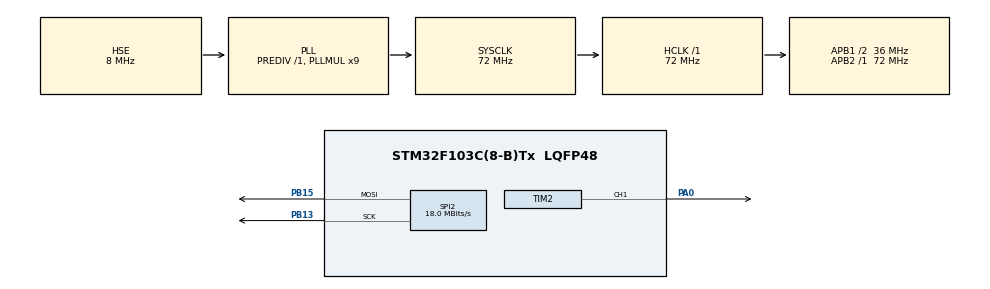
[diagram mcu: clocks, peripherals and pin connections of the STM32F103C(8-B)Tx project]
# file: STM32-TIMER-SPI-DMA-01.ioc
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Dma.Request0=SPI2_TX
Dma.SPI2_TX.0.Direction=DMA_MEMORY_TO_PERIPH
Dma.SPI2_TX.0.Instance=DMA1_Channel5
Dma.SPI2_TX.0.MemDataAlignment=DMA_MDATAALIGN_BYTE
Dma.SPI2_TX.0.MemInc=DMA_MINC_ENABLE
Dma.SPI2_TX.0.Mode=DMA_NORMAL
Dma.SPI2_TX.0.PeriphDataAlignment=DMA_PDATAALIGN_BYTE
Dma.SPI2_TX.0.PeriphInc=DMA_PINC_DISABLE
Dma.SPI2_TX.0.Priority=DMA_PRIORITY_LOW
Mcu.Family=STM32F1
Mcu.Name=STM32F103C(8-B)Tx
Mcu.Package=LQFP48
NVIC.DMA1_Channel5_IRQn=true\:0\:0\:false\:false\:true\:false\:true\:true
NVIC.PriorityGroup=NVIC_PRIORITYGROUP_4
NVIC.TIM2_IRQn=true\:0\:0\:false\:false\:true\:true\:true\:true
PA0-WKUP.Signal=S_TIM2_CH1_ETR
PA13.Mode=Serial_Wire
PA13.Signal=SYS_JTMS-SWDIO
PA14.Mode=Serial_Wire
PA14.Signal=SYS_JTCK-SWCLK
PB13.Mode=TX_Only_Simplex_Unidirect_Master
PB13.Signal=SPI2_SCK
PB15.Mode=TX_Only_Simplex_Unidirect_Master
PB15.Signal=SPI2_MOSI
PD0-OSC_IN.Mode=HSE-External-Oscillator
PD0-OSC_IN.Signal=RCC_OSC_IN
PD1-OSC_OUT.Mode=HSE-External-Oscillator
PD1-OSC_OUT.Signal=RCC_OSC_OUT
ProjectManager.HeapSize=0x200
ProjectManager.StackSize=0x400
ProjectManager.TargetToolchain=STM32CubeIDE
RCC.AHBFreq_Value=72000000
RCC.APB1CLKDivider=RCC_HCLK_DIV2
RCC.APB1Freq_Value=36000000
RCC.APB1TimFreq_Value=72000000
RCC.APB2Freq_Value=72000000
RCC.APB2TimFreq_Value=72000000
RCC.HCLKFreq_Value=72000000
RCC.PLLMUL=RCC_PLL_MUL9
RCC.PLLSourceVirtual=RCC_PLLSOURCE_HSE
RCC.SYSCLKFreq_VALUE=72000000
RCC.SYSCLKSource=RCC_SYSCLKSOURCE_PLLCLK
RCC.USBFreq_Value=72000000
SH.S_TIM2_CH1_ETR.0=TIM2_CH1,PWM Generation1 CH1
SPI2.CalculateBaudRate=18.0 MBits/s
SPI2.Direction=SPI_DIRECTION_2LINES
SPI2.Mode=SPI_MODE_MASTER
SPI2.VirtualType=VM_MASTER
TIM2.Channel-Output\ Compare2\ No\ Output=TIM_CHANNEL_2
TIM2.Channel-PWM\ Generation1\ CH1=TIM_CHANNEL_1
TIM2.Period=100-1
TIM2.Prescaler=72-1
TIM2.Pulse-Output\ Compare2\ No\ Output=5-1
TIM2.Pulse-PWM\ Generation1\ CH1=5-1
VP_TIM2_VS_ClockSourceINT.Mode=Internal
VP_TIM2_VS_no_output2.Mode=Output Compare2 No Output
board=custom

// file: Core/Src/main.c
/* USER CODE BEGIN Header */
/**
  ******************************************************************************
  * @file           : main.c
  * @brief          : Main program body
  ******************************************************************************
  * @attention
  *
  * Copyright (c) 2025 STMicroelectronics.
  * All rights reserved.
  *
  * This software is licensed under terms that can be found in the LICENSE file
  * in the root directory of this software component.
  * If no LICENSE file comes with this software, it is provided AS-IS.
  *
  ******************************************************************************
  */
/* USER CODE END Header */
#include "main.h"

SPI_HandleTypeDef hspi2;
DMA_HandleTypeDef hdma_spi2_tx;

TIM_HandleTypeDef htim2;

/* USER CODE BEGIN PV */

const uint8_t car = 0x55;
uint8_t TX_Buffer [] = {car, car, car, car, car, car, car, car, car, car
		, car, car, car, car, car, car, car, car, car, car
		, car, car, car, car, car, car, car, car, car, car
		, car, car, car, car, car, car, car, car, car, car
		, car, car, car, car, car, car, car, car, car, car} ; // DATA to send

/* USER CODE END PV */

void SystemClock_Config(void);
static void MX_GPIO_Init(void);
static void MX_DMA_Init(void);
static void MX_TIM2_Init(void);
static void MX_SPI2_Init(void);

int main(void)
{

  /* MCU Configuration--------------------------------------------------------*/

  /* Reset of all peripherals, Initializes the Flash interface and the Systick. */
  HAL_Init();

  /* Configure the system clock */
  SystemClock_Config();

  /* Initialize all configured peripherals */
  MX_GPIO_Init();
  MX_DMA_Init();
  MX_TIM2_Init();
  MX_SPI2_Init();
  /* USER CODE BEGIN 2 */
  HAL_TIM_PWM_Start(&htim2, TIM_CHANNEL_1);
  HAL_TIM_OC_Start_IT(&htim2, TIM_CHANNEL_2);
  //HAL_TIM_OC_Stop_IT(&htim2, TIM_CHANNEL_2);
  /* USER CODE END 2 */

  /* Infinite loop */
  while (1)
  {

  }
}

void SystemClock_Config(void)
{
  RCC_OscInitTypeDef RCC_OscInitStruct = {0};
  RCC_ClkInitTypeDef RCC_ClkInitStruct = {0};

  /** Initializes the RCC Oscillators according to the specified parameters
  * in the RCC_OscInitTypeDef structure.
  */
  RCC_OscInitStruct.OscillatorType = RCC_OSCILLATORTYPE_HSE;
  RCC_OscInitStruct.HSEState = RCC_HSE_ON;
  RCC_OscInitStruct.HSEPredivValue = RCC_HSE_PREDIV_DIV1;
  RCC_OscInitStruct.HSIState = RCC_HSI_ON;
  RCC_OscInitStruct.PLL.PLLState = RCC_PLL_ON;
  RCC_OscInitStruct.PLL.PLLSource = RCC_PLLSOURCE_HSE;
  RCC_OscInitStruct.PLL.PLLMUL = RCC_PLL_MUL9;
  if (HAL_RCC_OscConfig(&RCC_OscInitStruct) != HAL_OK)
  {
    Error_Handler();
  }

  /** Initializes the CPU, AHB and APB buses clocks
  */
  RCC_ClkInitStruct.ClockType = RCC_CLOCKTYPE_HCLK|RCC_CLOCKTYPE_SYSCLK
                              |RCC_CLOCKTYPE_PCLK1|RCC_CLOCKTYPE_PCLK2;
  RCC_ClkInitStruct.SYSCLKSource = RCC_SYSCLKSOURCE_PLLCLK;
  RCC_ClkInitStruct.AHBCLKDivider = RCC_SYSCLK_DIV1;
  RCC_ClkInitStruct.APB1CLKDivider = RCC_HCLK_DIV2;
  RCC_ClkInitStruct.APB2CLKDivider = RCC_HCLK_DIV1;

  if (HAL_RCC_ClockConfig(&RCC_ClkInitStruct, FLASH_LATENCY_2) != HAL_OK)
  {
    Error_Handler();
  }
}

static void MX_SPI2_Init(void)
{

  /* SPI2 parameter configuration*/
  hspi2.Instance = SPI2;
  hspi2.Init.Mode = SPI_MODE_MASTER;
  hspi2.Init.Direction = SPI_DIRECTION_2LINES;
  hspi2.Init.DataSize = SPI_DATASIZE_8BIT;
  hspi2.Init.CLKPolarity = SPI_POLARITY_LOW;
  hspi2.Init.CLKPhase = SPI_PHASE_1EDGE;
  hspi2.Init.NSS = SPI_NSS_SOFT;
  hspi2.Init.BaudRatePrescaler = SPI_BAUDRATEPRESCALER_2;
  hspi2.Init.FirstBit = SPI_FIRSTBIT_MSB;
  hspi2.Init.TIMode = SPI_TIMODE_DISABLE;
  hspi2.Init.CRCCalculation = SPI_CRCCALCULATION_DISABLE;
  hspi2.Init.CRCPolynomial = 10;
  if (HAL_SPI_Init(&hspi2) != HAL_OK)
  {
    Error_Handler();
  }

}

static void MX_TIM2_Init(void)
{

  TIM_ClockConfigTypeDef sClockSourceConfig = {0};
  TIM_MasterConfigTypeDef sMasterConfig = {0};
  TIM_OC_InitTypeDef sConfigOC = {0};

  htim2.Instance = TIM2;
  htim2.Init.Prescaler = 72-1;
  htim2.Init.CounterMode = TIM_COUNTERMODE_UP;
  htim2.Init.Period = 100-1;
  htim2.Init.ClockDivision = TIM_CLOCKDIVISION_DIV1;
  htim2.Init.AutoReloadPreload = TIM_AUTORELOAD_PRELOAD_DISABLE;
  if (HAL_TIM_Base_Init(&htim2) != HAL_OK)
  {
    Error_Handler();
  }
  sClockSourceConfig.ClockSource = TIM_CLOCKSOURCE_INTERNAL;
  if (HAL_TIM_ConfigClockSource(&htim2, &sClockSourceConfig) != HAL_OK)
  {
    Error_Handler();
  }
  if (HAL_TIM_PWM_Init(&htim2) != HAL_OK)
  {
    Error_Handler();
  }
  if (HAL_TIM_OC_Init(&htim2) != HAL_OK)
  {
    Error_Handler();
  }
  sMasterConfig.MasterOutputTrigger = TIM_TRGO_RESET;
  sMasterConfig.MasterSlaveMode = TIM_MASTERSLAVEMODE_DISABLE;
  if (HAL_TIMEx_MasterConfigSynchronization(&htim2, &sMasterConfig) != HAL_OK)
  {
    Error_Handler();
  }
  sConfigOC.OCMode = TIM_OCMODE_PWM1;
  sConfigOC.Pulse = 5-1;
  sConfigOC.OCPolarity = TIM_OCPOLARITY_HIGH;
  sConfigOC.OCFastMode = TIM_OCFAST_DISABLE;
  if (HAL_TIM_PWM_ConfigChannel(&htim2, &sConfigOC, TIM_CHANNEL_1) != HAL_OK)
  {
    Error_Handler();
  }
  sConfigOC.OCMode = TIM_OCMODE_TIMING;
  if (HAL_TIM_OC_ConfigChannel(&htim2, &sConfigOC, TIM_CHANNEL_2) != HAL_OK)
  {
    Error_Handler();
  }
  HAL_TIM_MspPostInit(&htim2);

}

static void MX_DMA_Init(void)
{

  /* DMA controller clock enable */
  __HAL_RCC_DMA1_CLK_ENABLE();

  /* DMA interrupt init */
  /* DMA1_Channel5_IRQn interrupt configuration */
  HAL_NVIC_SetPriority(DMA1_Channel5_IRQn, 0, 0);
  HAL_NVIC_EnableIRQ(DMA1_Channel5_IRQn);

}

static void MX_GPIO_Init(void)
{

  /* GPIO Ports Clock Enable */
  __HAL_RCC_GPIOD_CLK_ENABLE();
  __HAL_RCC_GPIOA_CLK_ENABLE();
  __HAL_RCC_GPIOB_CLK_ENABLE();

}

/* USER CODE BEGIN 4 */

void HAL_TIM_OC_DelayElapsedCallback(TIM_HandleTypeDef* htim)
{
    if(htim == &htim2)
    {
    	HAL_SPI_Transmit_DMA(&hspi2, TX_Buffer, 50);; //Sending in DMA mode
    }
}

/* USER CODE END 4 */

void Error_Handler(void)
{
  __disable_irq();
  while (1)
  {
  }
}
